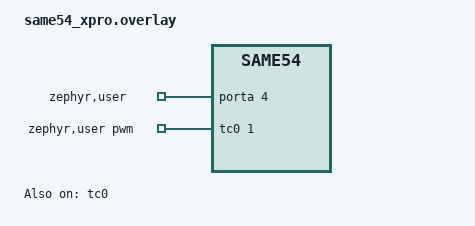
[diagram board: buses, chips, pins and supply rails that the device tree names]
/*
 * Copyright (c) 2025 Muhammed Asif
 * SPDX-License-Identifier: Apache-2.0
 *
 * Test requires jumper between:
 *  - PA04 -- PA05
 */

/ {
	zephyr,user {
		pwms = <&tc0 1 PWM_MSEC(2)>;
		gpios = <&porta 4 GPIO_ACTIVE_HIGH>;
	};
};

&tc0 {
	status = "okay";
	compatible = "atmel,sam0-tc-pwm";
	/* Gives a maximum period of 1.1s for 120MHz main clock */
	prescaler = <4>;
	#pwm-cells = <2>;

	pinctrl-0 = <&tc0_default>;
	pinctrl-names = "default";

	channels = <2>;
	counter-size = <32>;
};

&pinctrl {
	tc0_default: tc0_default {
		group1 {
			pinmux = <PA5E_TC0_WO1>;
		};
	};
};
